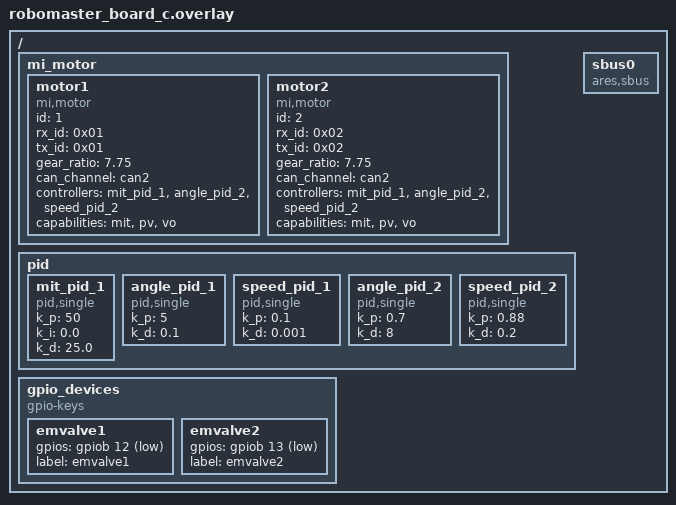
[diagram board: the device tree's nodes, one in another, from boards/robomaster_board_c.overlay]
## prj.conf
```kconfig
# 启用线程分析器
CONFIG_THREAD_ANALYZER=y
CONFIG_THREAD_ANALYZER_USE_LOG=y
CONFIG_THREAD_ANALYZER_USE_PRINTK=n
CONFIG_THREAD_NAME=y
# CONFIG_THREAD_ANALYZER_AUTO=y
# CONFIG_THREAD_ANALYZER_AUTO_INTERVAL=5
CONFIG_THREAD_ANALYZER_LOG_LEVEL_INF=y
CONFIG_THREAD_ANALYZER_AUTO_SEPARATE_CORES=n

# 启用 Shell 支持
CONFIG_SHELL=n
CONFIG_SHELL_BACKENDS=n
CONFIG_SHELL_BACKEND_SERIAL=n

# 启用 UART 控制台
CONFIG_UART_CONSOLE=y

# 禁用 SEGGER RTT
CONFIG_USE_SEGGER_RTT=n

# 启用事件支持
CONFIG_EVENTS=y

# 启用控制台支持
CONFIG_CONSOLE=y

# 启用串行支持
CONFIG_SERIAL=y
CONFIG_SPI_ASYNC=y
# 禁用优化
CONFIG_NO_OPTIMIZATIONS=y

# 启用驱动
CONFIG_MOTOR=y
CONFIG_MOTOR_DJI=y
# CONFIG_MOTOR_MI=y
CONFIG_MOTOR_LOG_LEVEL=4
CONFIG_CAN=y
CONFIG_MOTOR_INIT_PRIORITY=90
CONFIG_PID=y

CONFIG_ARES=y
CONFIG_ARES_SBUS=y
CONFIG_SBUS_INIT_PRIORITY=90

# use ASYNC uart API
CONFIG_SERIAL=y
CONFIG_UART_ASYNC_API=y
CONFIG_UART_INTERRUPT_DRIVEN=y

CONFIG_DMA=y
CONFIG_DMA_STM32=y  # STM32 DMA 驱动
CONFIG_UART_STM32=y # STM32 UART 驱动
# CONFIG_STM32_UART_DMA=y

# CONFIG_HAS_STM32CUBE=y
# CONFIG_USE_STM32_HAL_DMA=y
# CONFIG_SPI=y
# CONFIG_SPI_STM32=y

#
# Device Drivers
#
# CONFIG_SENSOR=y
# CONFIG_BMI08X=y
# CONFIG_BMI08X_ACCEL_TRIGGER_NONE is not set
# CONFIG_BMI08X_ACCEL_TRIGGER_GLOBAL_THREAD=y
# CONFIG_BMI08X_ACCEL_TRIGGER_OWN_THREAD is not set
# CONFIG_BMI08X_GYRO_TRIGGER_NONE is not set
# CONFIG_BMI08X_GYRO_TRIGGER_GLOBAL_THREAD=y
# CONFIG_BMI08X_GYRO_TRIGGER_OWN_THREAD is not set
# CONFIG_BMI08X_I2C_WRITE_BURST_SIZE=16

CONFIG_DEBUG_THREAD_INFO=y

CONFIG_MAIN_STACK_SIZE=4096
```

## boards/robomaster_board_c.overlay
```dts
/ {
    // rm_motor {
    //     motor0: motor0{
    //         compatible = "dji,motor";
    //         is_m2006;
    //         id = <3>;
    //         rx_id = <0x203>;
    //         tx_id = <0x200>;
    //         gear_ratio = "36";
    //         status = "okay";
    //         can_channel = <&can1>;
    //         controllers = <&angle_pid_1 &speed_pid_1>;
    //         capabilities = "angle", "speed";
    //     };

    //     motor1: motor1{
    //         compatible = "dji,motor";
    //         is_m2006;
    //         id = <4>;
    //         rx_id = <0x204>;
    //         tx_id = <0x200>;
    //         gear_ratio = "36";
    //         status = "okay";
    //         can_channel = <&can1>;
    //         controllers = <&angle_pid_1 &speed_pid_1>;
    //         capabilities = "angle", "speed";
    //     };
    // };
    mi_motor{
        motor1: motor1{
            compatible = "mi,motor";
            id = <1>;
            rx_id = <0x01>;
            tx_id = <0x01>;
            gear_ratio = "7.75";
            status = "okay";
            can_channel = <&can2>;
            controllers = <&mit_pid_1 &angle_pid_2 &speed_pid_2>;
            capabilities = "mit", "pv", "vo";
        };
        
        motor2: motor2{
            compatible = "mi,motor";
            id = <2>;
            rx_id = <0x02>;
            tx_id = <0x02>;
            gear_ratio = "7.75";
            status = "okay";
            can_channel = <&can2>;
            controllers = <&mit_pid_1 &angle_pid_2 &speed_pid_2>;
            capabilities = "mit", "pv", "vo";
        };

    };
    pid {
		mit_pid_1: mit_pid_1 {
			#controller-cells = <0>;
			compatible = "pid,single";
			k_p = "50";
			k_i = "0.0";
			k_d = "25.0";
		};
		angle_pid_1: angle_pid_1 {
			#controller-cells = <0>;
			compatible = "pid,single";
			k_p = "5";
			k_d = "0.1";
		};
		speed_pid_1: speed_pid_1 {
			#controller-cells = <0>;
			compatible = "pid,single";
			k_p = "0.1";
			k_d = "0.001";
		};
        angle_pid_2: angle_pid_2 {
			#controller-cells = <0>;
			compatible = "pid,single";
			k_p = "0.7";
			k_d = "8";
		};
		speed_pid_2: speed_pid_2 {
			#controller-cells = <0>;
			compatible = "pid,single";
			k_p = "0.88";
			k_d = "0.2";
		};
	};
    
    gpio_devices {
        compatible = "gpio-keys"; // 或者使用其他合适的compatible
        
        emvalve1: emvalve1 {
            gpios = <&gpiob 12 GPIO_ACTIVE_LOW>;
            label = "emvalve1";
        };
        ;
        emvalve2: emvalve2 {
            gpios = <&gpiob 13 GPIO_ACTIVE_LOW>;
            label = "emvalve2";
        };
    };

    sbus0: sbus0 {
        compatible = "ares,sbus";
        status = "okay";
    };
};
```

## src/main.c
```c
#include "zephyr/drivers/gpio.h"
#include "ares/board/init.h"
#include <stdbool.h>
#include <stddef.h>
#include <stdint.h>
#include <stdio.h>
#include <math.h>
#include <zephyr/device.h>
#include <zephyr/logging/log.h>
#include <zephyr/devicetree.h>
#include <zephyr/drivers/can.h>
#include <zephyr/debug/thread_analyzer.h>
#include <zephyr/kernel.h>
#include <zephyr/sys/printk.h>
#include <zephyr/drivers/uart.h>
#include <zephyr/drivers/motor.h>
#include <zephyr/drivers/sbus.h>
#include <zephyr/drivers/sensor.h>

#define MOTOR1_NODE DT_NODELABEL(motor2)
#define MOTOR2_NODE DT_NODELABEL(motor1)

#define SBUS_NODE DT_NODELABEL(sbus0)
#define EMValve1 DT_NODELABEL(emvalve1)
#define EMValve2 DT_NODELABEL(emvalve2)
//const struct device *motor1 = DEVICE_DT_GET(MOTOR1_NODE);//M2006
//const struct device *motor2 = DEVICE_DT_GET(MOTOR2_NODE);//M2006
const struct device *sbus = DEVICE_DT_GET(SBUS_NODE);
const struct gpio_dt_spec emvalve1 = GPIO_DT_SPEC_GET_BY_IDX(EMValve1, gpios, 0);
const struct gpio_dt_spec emvalve2 = GPIO_DT_SPEC_GET_BY_IDX(EMValve2, gpios, 0);
const struct device *motor1 = DEVICE_DT_GET(MOTOR1_NODE);
const struct device *motor2 = DEVICE_DT_GET(MOTOR2_NODE);

int sbus_get_bool(const struct device *sbus, int channel)
{
	sbus_get_digit(sbus, channel);
	return (int)sbus_get_percent(sbus, channel) > 0.5;
}

static bool arm_position_reached_90 = false;
static bool arm_position_reached_60 = false;
float current_angle2 = 0.0f; // 当前电机2角度（推射抬升mi）

void execute_arm_control(void)//大臂
{
    current_angle2 = motor_get_angle(motor2);
    if (sbus_get_percent(sbus, 7) > 0.5f) {
        if (!arm_position_reached_90) { // 只有未完成抬升时才执行
            // 逐渐抬升到 -80.0f
            for (int i = 1; i <= 10; i++) {
                float target_angle = ((-86.0f - current_angle2) * (float)i / 10.0f) + current_angle2;
                motor_set_mit(motor2, 0.0f, target_angle, -0.6f);
                k_msleep(60);
            }
            arm_position_reached_90 = true; // 标记为已完成抬升
            arm_position_reached_60 = false; // 重置状态
        }
    } 
    
    else if(sbus_get_percent(sbus, 7) == 0.0f) {
        if (!arm_position_reached_60) { // 只有未完成抬升时才执行
            // 逐渐抬升到 -60.0f
            for (int i = 1; i <= 10; i++) {
                float target_angle = ((-60.0f - current_angle2) * (float)i / 10.0f) + current_angle2;
                motor_set_mit(motor2, 0.0f, target_angle, 0.1f);
                k_msleep(30);
            }
            arm_position_reached_60 = true; // 标记为已完成抬升
            arm_position_reached_90 = false; // 重置状态
        }
    }
    
    else {
        if (arm_position_reached_60 || arm_position_reached_90) { // 只有未完成下降时才执行
            // 逐渐下降到 0.0f
            for (int i = 1; i <= 10; i++) {
                float target_angle = ((0.0f - current_angle2) * (float)i / 10.0f) + current_angle2;
                motor_set_mit(motor2, 0.0f, target_angle, 1.5f);
                k_msleep(60);
            }
            arm_position_reached_60 = false;
            arm_position_reached_90 = false; // 标记为已完成下降
        }
    }
}
int main(void)
{
    gpio_pin_configure_dt(&emvalve1, GPIO_OUTPUT_ACTIVE);
    gpio_pin_configure_dt(&emvalve2, GPIO_OUTPUT_ACTIVE);
    
    // 明确设置初始状态
    gpio_pin_set_dt(&emvalve1, false);  // 不推球
    gpio_pin_set_dt(&emvalve2, true);   // 吸球（默认状态）
    
    // 等待SBUS准备就绪
    k_msleep(500);
    while(1){
    if(sbus_get_bool(sbus, 6)){
    //k_msleep(100);
        gpio_pin_set_dt(&emvalve1, true);//推球
        // k_msleep(100);
        gpio_pin_set_dt(&emvalve2, false);//不吸球
    }
    else {
        gpio_pin_set_dt(&emvalve1, false);//不推球
        gpio_pin_set_dt(&emvalve2, true);//吸球  
    }
    k_msleep(10);
}
    // motor_control(motor1, SET_ZERO);
    // k_msleep(1);
    // motor_control(motor2, SET_ZERO);
    // k_msleep(1);

    // float current_angle1 = 0.0f; // 当前电机3角度
    // float current_angle2 = 0.0f; // 当前电机4角度
    // current_angle1 = motor_get_angle(motor1);
    // current_angle2 = motor_get_angle(motor2);

    // for (int i = 1; i < 19; i++) {
    //     float target_angle1 = ((230.0f - current_angle1) * (float)((i/18.0f)*(i/18.0f))) + current_angle1;
    //     float target_angle2 = ((-230.0f - current_angle2) * (float)((i/18.0f)*(i/18.0f))) + current_angle2;
        
    //     motor_set_angle(motor1, target_angle1);
    //     motor_set_angle(motor2, target_angle2);

    //     k_msleep(10);
    // }
    // float current_speed1 = 0.0f;
    // float current_speed2 = 0.0f;
    // for (int i = 1; i < 19; i++) {
    //     float target_speed1 = ((i/18.0f)*(i/18.0f))*30.0f;
    //     float target_speed2 = -((i/18.0f)*(i/18.0f))*30.0f;
        
    //     motor_set_speed(motor1, target_speed1);
    //     motor_set_speed(motor2, target_speed2);

    //     k_msleep(50);
    // }
    // motor_set_speed(motor1, 0.0f);
    // motor_set_speed(motor2, 0.0f);

    
}
```
